VERSION ""

NS_ :

BS_:

BU_: ECU

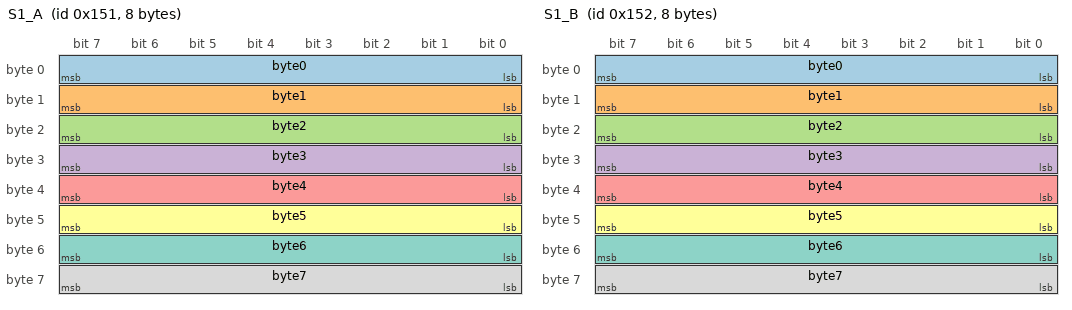
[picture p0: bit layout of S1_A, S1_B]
BO_ 337 S1_A: 8 ECU
 SG_ byte0 : 0|8@1+ (1,0) [0|255] "" ECU
 SG_ byte1 : 8|8@1+ (1,0) [0|255] "" ECU
 SG_ byte2 : 16|8@1+ (1,0) [0|255] "" ECU
 SG_ byte3 : 24|8@1+ (1,0) [0|255] "" ECU
 SG_ byte4 : 32|8@1+ (1,0) [0|255] "" ECU
 SG_ byte5 : 40|8@1+ (1,0) [0|255] "" ECU
 SG_ byte6 : 48|8@1+ (1,0) [0|255] "" ECU
 SG_ byte7 : 56|8@1+ (1,0) [0|255] "" ECU

BO_ 338 S1_B: 8 ECU
 SG_ byte0 : 0|8@1+ (1,0) [0|255] "" ECU
 SG_ byte1 : 8|8@1+ (1,0) [0|255] "" ECU
 SG_ byte2 : 16|8@1+ (1,0) [0|255] "" ECU
 SG_ byte3 : 24|8@1+ (1,0) [0|255] "" ECU
 SG_ byte4 : 32|8@1+ (1,0) [0|255] "" ECU
 SG_ byte5 : 40|8@1+ (1,0) [0|255] "" ECU
 SG_ byte6 : 48|8@1+ (1,0) [0|255] "" ECU
 SG_ byte7 : 56|8@1+ (1,0) [0|255] "" ECU

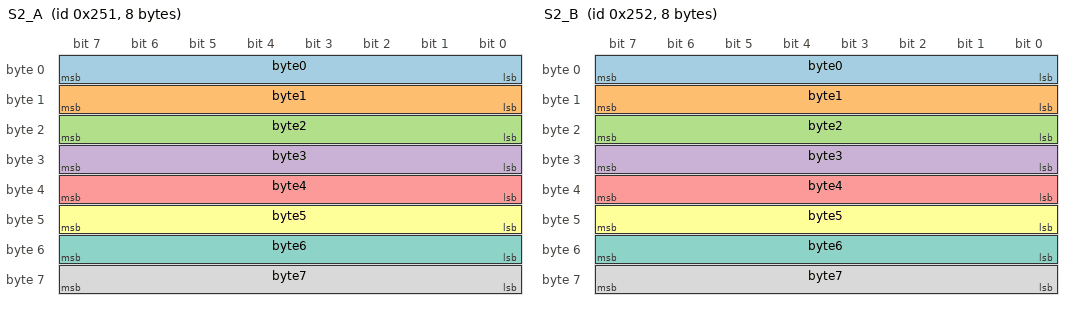
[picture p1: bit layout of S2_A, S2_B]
BO_ 593 S2_A: 8 ECU
 SG_ byte0 : 0|8@1+ (1,0) [0|255] "" ECU
 SG_ byte1 : 8|8@1+ (1,0) [0|255] "" ECU
 SG_ byte2 : 16|8@1+ (1,0) [0|255] "" ECU
 SG_ byte3 : 24|8@1+ (1,0) [0|255] "" ECU
 SG_ byte4 : 32|8@1+ (1,0) [0|255] "" ECU
 SG_ byte5 : 40|8@1+ (1,0) [0|255] "" ECU
 SG_ byte6 : 48|8@1+ (1,0) [0|255] "" ECU
 SG_ byte7 : 56|8@1+ (1,0) [0|255] "" ECU

BO_ 594 S2_B: 8 ECU
 SG_ byte0 : 0|8@1+ (1,0) [0|255] "" ECU
 SG_ byte1 : 8|8@1+ (1,0) [0|255] "" ECU
 SG_ byte2 : 16|8@1+ (1,0) [0|255] "" ECU
 SG_ byte3 : 24|8@1+ (1,0) [0|255] "" ECU
 SG_ byte4 : 32|8@1+ (1,0) [0|255] "" ECU
 SG_ byte5 : 40|8@1+ (1,0) [0|255] "" ECU
 SG_ byte6 : 48|8@1+ (1,0) [0|255] "" ECU
 SG_ byte7 : 56|8@1+ (1,0) [0|255] "" ECU

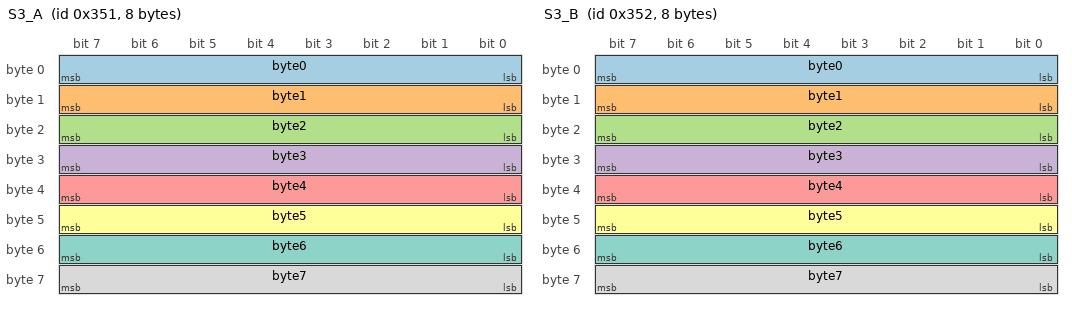
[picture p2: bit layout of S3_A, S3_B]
BO_ 849 S3_A: 8 ECU
 SG_ byte0 : 0|8@1+ (1,0) [0|255] "" ECU
 SG_ byte1 : 8|8@1+ (1,0) [0|255] "" ECU
 SG_ byte2 : 16|8@1+ (1,0) [0|255] "" ECU
 SG_ byte3 : 24|8@1+ (1,0) [0|255] "" ECU
 SG_ byte4 : 32|8@1+ (1,0) [0|255] "" ECU
 SG_ byte5 : 40|8@1+ (1,0) [0|255] "" ECU
 SG_ byte6 : 48|8@1+ (1,0) [0|255] "" ECU
 SG_ byte7 : 56|8@1+ (1,0) [0|255] "" ECU

BO_ 850 S3_B: 8 ECU
 SG_ byte0 : 0|8@1+ (1,0) [0|255] "" ECU
 SG_ byte1 : 8|8@1+ (1,0) [0|255] "" ECU
 SG_ byte2 : 16|8@1+ (1,0) [0|255] "" ECU
 SG_ byte3 : 24|8@1+ (1,0) [0|255] "" ECU
 SG_ byte4 : 32|8@1+ (1,0) [0|255] "" ECU
 SG_ byte5 : 40|8@1+ (1,0) [0|255] "" ECU
 SG_ byte6 : 48|8@1+ (1,0) [0|255] "" ECU
 SG_ byte7 : 56|8@1+ (1,0) [0|255] "" ECU

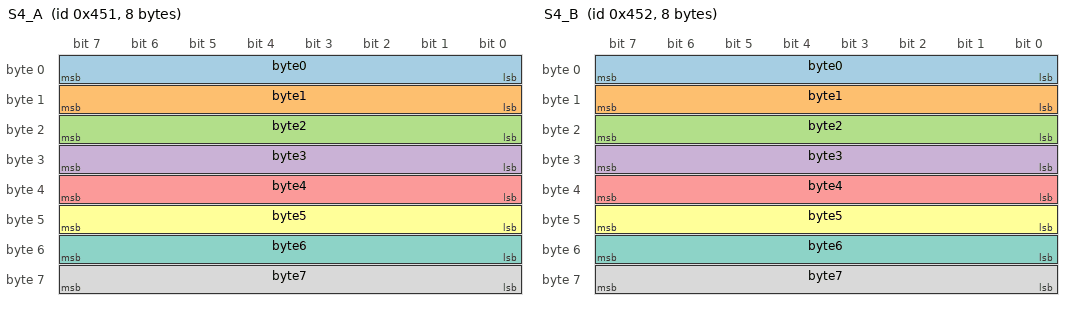
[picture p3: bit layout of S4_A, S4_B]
BO_ 1105 S4_A: 8 ECU
 SG_ byte0 : 0|8@1+ (1,0) [0|255] "" ECU
 SG_ byte1 : 8|8@1+ (1,0) [0|255] "" ECU
 SG_ byte2 : 16|8@1+ (1,0) [0|255] "" ECU
 SG_ byte3 : 24|8@1+ (1,0) [0|255] "" ECU
 SG_ byte4 : 32|8@1+ (1,0) [0|255] "" ECU
 SG_ byte5 : 40|8@1+ (1,0) [0|255] "" ECU
 SG_ byte6 : 48|8@1+ (1,0) [0|255] "" ECU
 SG_ byte7 : 56|8@1+ (1,0) [0|255] "" ECU

BO_ 1106 S4_B: 8 ECU
 SG_ byte0 : 0|8@1+ (1,0) [0|255] "" ECU
 SG_ byte1 : 8|8@1+ (1,0) [0|255] "" ECU
 SG_ byte2 : 16|8@1+ (1,0) [0|255] "" ECU
 SG_ byte3 : 24|8@1+ (1,0) [0|255] "" ECU
 SG_ byte4 : 32|8@1+ (1,0) [0|255] "" ECU
 SG_ byte5 : 40|8@1+ (1,0) [0|255] "" ECU
 SG_ byte6 : 48|8@1+ (1,0) [0|255] "" ECU
 SG_ byte7 : 56|8@1+ (1,0) [0|255] "" ECU

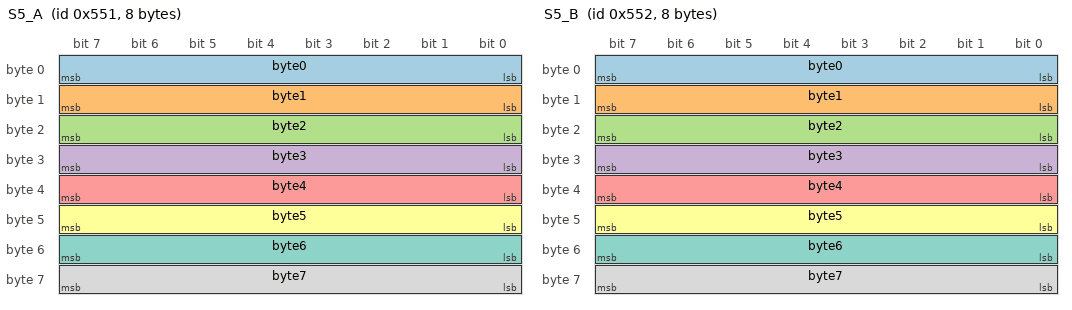
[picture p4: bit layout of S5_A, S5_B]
BO_ 1361 S5_A: 8 ECU
 SG_ byte0 : 0|8@1+ (1,0) [0|255] "" ECU
 SG_ byte1 : 8|8@1+ (1,0) [0|255] "" ECU
 SG_ byte2 : 16|8@1+ (1,0) [0|255] "" ECU
 SG_ byte3 : 24|8@1+ (1,0) [0|255] "" ECU
 SG_ byte4 : 32|8@1+ (1,0) [0|255] "" ECU
 SG_ byte5 : 40|8@1+ (1,0) [0|255] "" ECU
 SG_ byte6 : 48|8@1+ (1,0) [0|255] "" ECU
 SG_ byte7 : 56|8@1+ (1,0) [0|255] "" ECU

BO_ 1362 S5_B: 8 ECU
 SG_ byte0 : 0|8@1+ (1,0) [0|255] "" ECU
 SG_ byte1 : 8|8@1+ (1,0) [0|255] "" ECU
 SG_ byte2 : 16|8@1+ (1,0) [0|255] "" ECU
 SG_ byte3 : 24|8@1+ (1,0) [0|255] "" ECU
 SG_ byte4 : 32|8@1+ (1,0) [0|255] "" ECU
 SG_ byte5 : 40|8@1+ (1,0) [0|255] "" ECU
 SG_ byte6 : 48|8@1+ (1,0) [0|255] "" ECU
 SG_ byte7 : 56|8@1+ (1,0) [0|255] "" ECU

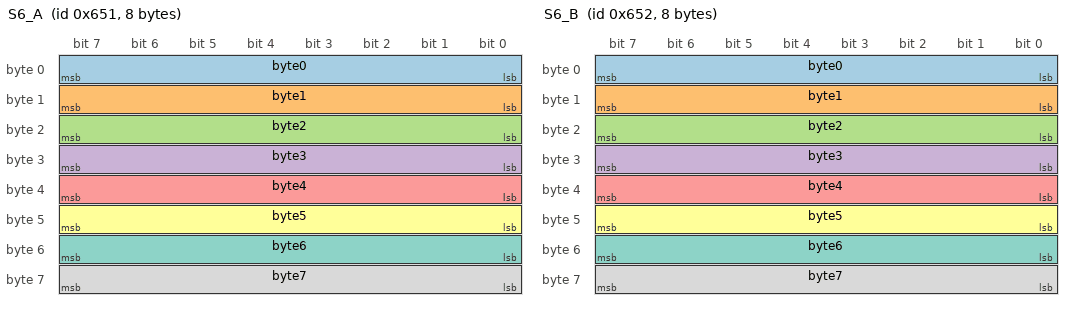
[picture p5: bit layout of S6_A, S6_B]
BO_ 1617 S6_A: 8 ECU
 SG_ byte0 : 0|8@1+ (1,0) [0|255] "" ECU
 SG_ byte1 : 8|8@1+ (1,0) [0|255] "" ECU
 SG_ byte2 : 16|8@1+ (1,0) [0|255] "" ECU
 SG_ byte3 : 24|8@1+ (1,0) [0|255] "" ECU
 SG_ byte4 : 32|8@1+ (1,0) [0|255] "" ECU
 SG_ byte5 : 40|8@1+ (1,0) [0|255] "" ECU
 SG_ byte6 : 48|8@1+ (1,0) [0|255] "" ECU
 SG_ byte7 : 56|8@1+ (1,0) [0|255] "" ECU

BO_ 1618 S6_B: 8 ECU
 SG_ byte0 : 0|8@1+ (1,0) [0|255] "" ECU
 SG_ byte1 : 8|8@1+ (1,0) [0|255] "" ECU
 SG_ byte2 : 16|8@1+ (1,0) [0|255] "" ECU
 SG_ byte3 : 24|8@1+ (1,0) [0|255] "" ECU
 SG_ byte4 : 32|8@1+ (1,0) [0|255] "" ECU
 SG_ byte5 : 40|8@1+ (1,0) [0|255] "" ECU
 SG_ byte6 : 48|8@1+ (1,0) [0|255] "" ECU
 SG_ byte7 : 56|8@1+ (1,0) [0|255] "" ECU
